AUTOSAR XML (schema 00048)
package /AdaptiveApplicationSwComponent
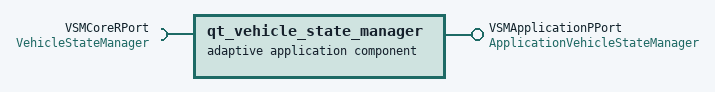
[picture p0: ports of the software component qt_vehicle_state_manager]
  adaptive application sw component type qt_vehicle_state_manager
    provide port VSMApplicationPPort: provided-interface=ApplicationVehicleStateManager
    require port VSMCoreRPort: required-interface=VehicleStateManager
package /Executables
  executable qt_vehicle_state_manager
    root sw component prototype qt_vehicle_state_manager_root: application-type=qt_vehicle_state_manager
package /ProcessDesign
  process design qt_vehicle_state_manager: executable=qt_vehicle_state_manager
package /Processes
  process qt_vehicle_state_manager: design=qt_vehicle_state_manager, executable=qt_vehicle_state_manager, state-dependent-startup-config{function-group-state=UcmMasterApplicationStates.Ucm_Master_Application1, resource-group=ResourceGroup, startup-config=qt_vehicle_state_manager}
